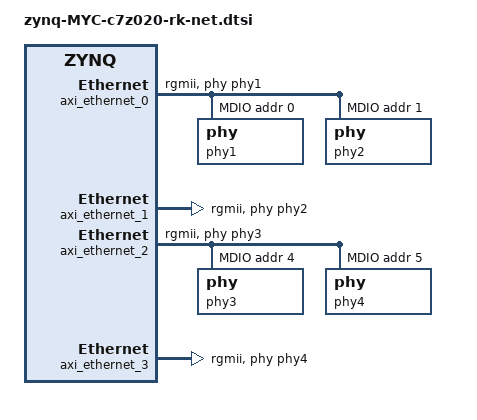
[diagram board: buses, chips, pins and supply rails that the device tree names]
/*
 * CAUTION: This file is automatically generated by Xilinx.
 * Version:  
 * Today is: Wed Mar 20 09:21:30 2019
 */


/ {
	amba_pl: amba_pl {
		#address-cells = <1>;
		#size-cells = <1>;
		compatible = "simple-bus";
		ranges ;
		axi_dma_0: dma@40400000 {
			#dma-cells = <1>;
			axistream-connected = <&axi_ethernet_0>;
			axistream-control-connected = <&axi_ethernet_0>;
			clock-names = "s_axi_lite_aclk", "m_axi_sg_aclk", "m_axi_mm2s_aclk", "m_axi_s2mm_aclk";
			clocks = <&clkc 15>, <&clkc 15>, <&clkc 15>, <&clkc 15>;
			compatible = "xlnx,eth-dma";
			interrupt-names = "mm2s_introut", "s2mm_introut";
			interrupt-parent = <&intc>;
			interrupts = <0 29 4 0 30 4>;
			reg = <0x40400000 0x10000>;
			xlnx,include-dre ;
		};
		axi_dma_1: dma@40410000 {
			#dma-cells = <1>;
			axistream-connected = <&axi_ethernet_1>;
			axistream-control-connected = <&axi_ethernet_1>;
			clock-names = "s_axi_lite_aclk", "m_axi_sg_aclk", "m_axi_mm2s_aclk", "m_axi_s2mm_aclk";
			clocks = <&clkc 15>, <&clkc 15>, <&clkc 15>, <&clkc 15>;
			compatible = "xlnx,eth-dma";
			interrupt-names = "mm2s_introut", "s2mm_introut";
			interrupt-parent = <&intc>;
			interrupts = <0 33 4 0 34 4>;
			reg = <0x40410000 0x10000>;
			xlnx,include-dre ;
		};
		axi_dma_2: dma@40420000 {
			#dma-cells = <1>;
			axistream-connected = <&axi_ethernet_2>;
			axistream-control-connected = <&axi_ethernet_2>;
			clock-names = "s_axi_lite_aclk", "m_axi_sg_aclk", "m_axi_mm2s_aclk", "m_axi_s2mm_aclk";
			clocks = <&clkc 15>, <&clkc 15>, <&clkc 15>, <&clkc 15>;
			compatible = "xlnx,eth-dma";
			interrupt-names = "mm2s_introut", "s2mm_introut";
			interrupt-parent = <&intc>;
			interrupts = <0 54 4 0 55 4>;
			reg = <0x40420000 0x10000>;
			xlnx,include-dre ;
		};
		axi_dma_3: dma@40430000 {
			#dma-cells = <1>;
			axistream-connected = <&axi_ethernet_3>;
			axistream-control-connected = <&axi_ethernet_3>;
			clock-names = "s_axi_lite_aclk", "m_axi_sg_aclk", "m_axi_mm2s_aclk", "m_axi_s2mm_aclk";
			clocks = <&clkc 15>, <&clkc 15>, <&clkc 15>, <&clkc 15>;
			compatible = "xlnx,eth-dma";
			interrupt-names = "mm2s_introut", "s2mm_introut";
			interrupt-parent = <&intc>;
			interrupts = <0 58 4 0 59 4>;
			reg = <0x40430000 0x10000>;
			xlnx,include-dre ;
		};
		axi_ethernet_0: ethernet@41000000 {
			axistream-connected = <&axi_dma_0>;
			axistream-control-connected = <&axi_dma_0>;
			clock-frequency = <100000000>;
			clock-names = "s_axi_lite_clk", "axis_clk", "gtx_clk", "ref_clk";
			clocks = <&clkc 15>, <&clkc 15>, <&clkc 16>, <&clkc 17>;
			compatible = "xlnx,axi-ethernet-7.1", "xlnx,axi-ethernet-1.00.a";
			device_type = "network";
			interrupt-names = "mac_irq", "interrupt";
			interrupt-parent = <&intc>;
			interrupts = <0 31 1 0 32 4>;
			local-mac-address = [00 0a 35 00 00 00];
			phy-handle = <&phy1>;
			phy-mode = "rgmii";
			reg = <0x41000000 0x40000>;
			xlnx = <0x0>;
			xlnx,axiliteclkrate = <0x0>;
			xlnx,axisclkrate = <0x0>;
			xlnx,clockselection = <0x0>;
			xlnx,enableasyncsgmii = <0x0>;
			xlnx,gt-type = <0x0>;
			xlnx,gtinex = <0x0>;
			xlnx,gtlocation = <0x0>;
			xlnx,gtrefclksrc = <0x0>;
			xlnx,include-dre ;
			xlnx,instantiatebitslice0 = <0x0>;
			xlnx,phy-type = <0x3>;
			xlnx,phyaddr = <0x1>;
			xlnx,rable = <0x0>;
			xlnx,rxcsum = <0x2>;
			xlnx,rxlane0-placement = <0x0>;
			xlnx,rxlane1-placement = <0x0>;
			xlnx,rxmem = <0x4000>;
			xlnx,rxnibblebitslice0used = <0x0>;
			xlnx,tx-in-upper-nibble = <0x1>;
			xlnx,txcsum = <0x2>;
			xlnx,txlane0-placement = <0x0>;
			xlnx,txlane1-placement = <0x0>;
			axi_ethernet_0_mdio: mdio {
				#address-cells = <1>;
				#size-cells = <0>;

				phy1: phy@0 {
					reg = <0>;
				};
				phy2: phy@1 {
					reg = <1>;
				};    
			};
		};
		axi_ethernet_1: ethernet@41040000 {
			axistream-connected = <&axi_dma_1>;
			axistream-control-connected = <&axi_dma_1>;
			clock-frequency = <100000000>;
			clock-names = "s_axi_lite_clk", "axis_clk", "gtx_clk", "gtx_clk90";
			clocks = <&clkc 15>, <&clkc 15>, <&misc_clk_0>, <&misc_clk_0>;
			compatible = "xlnx,axi-ethernet-7.1", "xlnx,axi-ethernet-1.00.a";
			device_type = "network";
			interrupt-names = "mac_irq", "interrupt";
			interrupt-parent = <&intc>;
			interrupts = <0 35 1 0 36 4>;
			local-mac-address = [00 0a 35 00 00 01];
			phy-handle = <&phy2>;
			phy-mode = "rgmii";
			reg = <0x41040000 0x40000>;
			xlnx = <0x0>;
			xlnx,axiliteclkrate = <0x0>;
			xlnx,axisclkrate = <0x0>;
			xlnx,clockselection = <0x0>;
			xlnx,enableasyncsgmii = <0x0>;
			xlnx,gt-type = <0x0>;
			xlnx,gtinex = <0x0>;
			xlnx,gtlocation = <0x0>;
			xlnx,gtrefclksrc = <0x0>;
			xlnx,include-dre ;
			xlnx,instantiatebitslice0 = <0x0>;
			xlnx,phy-type = <0x3>;
			xlnx,phyaddr = <0x1>;
			xlnx,rable = <0x0>;
			xlnx,rxcsum = <0x2>;
			xlnx,rxlane0-placement = <0x0>;
			xlnx,rxlane1-placement = <0x0>;
			xlnx,rxmem = <0x4000>;
			xlnx,rxnibblebitslice0used = <0x0>;
			xlnx,tx-in-upper-nibble = <0x1>;
			xlnx,txcsum = <0x2>;
			xlnx,txlane0-placement = <0x0>;
			xlnx,txlane1-placement = <0x0>;
			// axi_ethernet_1_mdio: mdio {
			// 	#address-cells = <1>;
			// 	#size-cells = <0>;
			// };
		};
		misc_clk_0: misc_clk_0 {
			#clock-cells = <0>;
			clock-frequency = <125000000>;
			compatible = "fixed-clock";
		};
		axi_ethernet_2: ethernet@41080000 {
			axistream-connected = <&axi_dma_2>;
			axistream-control-connected = <&axi_dma_2>;
			clock-frequency = <100000000>;
			clock-names = "s_axi_lite_clk", "axis_clk", "gtx_clk", "gtx_clk90";
			clocks = <&clkc 15>, <&clkc 15>, <&misc_clk_0>, <&misc_clk_0>;
			compatible = "xlnx,axi-ethernet-7.1", "xlnx,axi-ethernet-1.00.a";
			device_type = "network";
			interrupt-names = "mac_irq", "interrupt";
			interrupt-parent = <&intc>;
			interrupts = <0 52 1 0 53 4>;
			local-mac-address = [00 0a 35 00 00 02];
			phy-handle = <&phy3>;
			phy-mode = "rgmii";
			reg = <0x41080000 0x40000>;
			xlnx = <0x0>;
			xlnx,axiliteclkrate = <0x0>;
			xlnx,axisclkrate = <0x0>;
			xlnx,clockselection = <0x0>;
			xlnx,enableasyncsgmii = <0x0>;
			xlnx,gt-type = <0x0>;
			xlnx,gtinex = <0x0>;
			xlnx,gtlocation = <0x0>;
			xlnx,gtrefclksrc = <0x0>;
			xlnx,include-dre ;
			xlnx,instantiatebitslice0 = <0x0>;
			xlnx,phy-type = <0x3>;
			xlnx,phyaddr = <0x1>;
			xlnx,rable = <0x0>;
			xlnx,rxcsum = <0x2>;
			xlnx,rxlane0-placement = <0x0>;
			xlnx,rxlane1-placement = <0x0>;
			xlnx,rxmem = <0x4000>;
			xlnx,rxnibblebitslice0used = <0x0>;
			xlnx,tx-in-upper-nibble = <0x1>;
			xlnx,txcsum = <0x2>;
			xlnx,txlane0-placement = <0x0>;
			xlnx,txlane1-placement = <0x0>;
			axi_ethernet_2_mdio: mdio {
				#address-cells = <1>;
				#size-cells = <0>;

				phy3: phy@2 {
					//compatible = "atheros,ar8035";
					//device_type = "ethernet-phy";
					reg = <4>;
				};
				phy4: phy@3 {
					reg = <5>;
				};   
			};
		};
		axi_ethernet_3: ethernet@410c0000 {
			axistream-connected = <&axi_dma_3>;
			axistream-control-connected = <&axi_dma_3>;
			clock-frequency = <100000000>;
			clock-names = "s_axi_lite_clk", "axis_clk", "gtx_clk", "gtx_clk90";
			clocks = <&clkc 15>, <&clkc 15>, <&misc_clk_0>, <&misc_clk_0>;
			compatible = "xlnx,axi-ethernet-7.1", "xlnx,axi-ethernet-1.00.a";
			device_type = "network";
			interrupt-names = "mac_irq", "interrupt";
			interrupt-parent = <&intc>;
			interrupts = <0 56 1 0 57 4>;
			local-mac-address = [00 0a 35 00 00 03];
			phy-handle = <&phy4>;
			phy-mode = "rgmii";
			reg = <0x410c0000 0x40000>;
			xlnx = <0x0>;
			xlnx,axiliteclkrate = <0x0>;
			xlnx,axisclkrate = <0x0>;
			xlnx,clockselection = <0x0>;
			xlnx,enableasyncsgmii = <0x0>;
			xlnx,gt-type = <0x0>;
			xlnx,gtinex = <0x0>;
			xlnx,gtlocation = <0x0>;
			xlnx,gtrefclksrc = <0x0>;
			xlnx,include-dre ;
			xlnx,instantiatebitslice0 = <0x0>;
			xlnx,phy-type = <0x3>;
			xlnx,phyaddr = <0x1>;
			xlnx,rable = <0x0>;
			xlnx,rxcsum = <0x2>;
			xlnx,rxlane0-placement = <0x0>;
			xlnx,rxlane1-placement = <0x0>;
			xlnx,rxmem = <0x4000>;
			xlnx,rxnibblebitslice0used = <0x0>;
			xlnx,tx-in-upper-nibble = <0x1>;
			xlnx,txcsum = <0x2>;
			xlnx,txlane0-placement = <0x0>;
			xlnx,txlane1-placement = <0x0>;
			// axi_ethernet_3_mdio: mdio {
			// 	#address-cells = <1>;
			// 	#size-cells = <0>;
			// };
		};
	};
};
